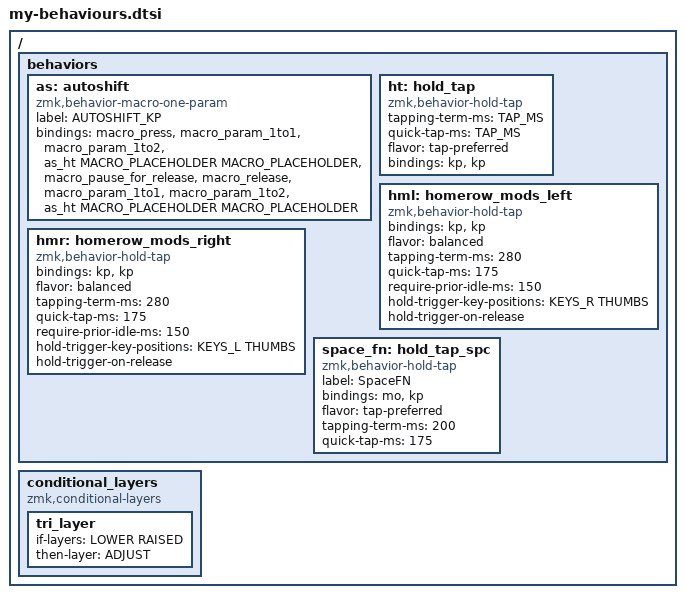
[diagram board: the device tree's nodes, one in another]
/ {
    behaviors {
    
        as: autoshift {
            compatible = "zmk,behavior-macro-one-param";
            #binding-cells = <1>;
            label = "AUTOSHIFT_KP";
            bindings =
              <&macro_press>,
              <&macro_param_1to1>,
              <&macro_param_1to2>,
              <&as_ht MACRO_PLACEHOLDER MACRO_PLACEHOLDER>,
              <&macro_pause_for_release>,
              <&macro_release>,
              <&macro_param_1to1>,
              <&macro_param_1to2>,
              <&as_ht MACRO_PLACEHOLDER MACRO_PLACEHOLDER>;
          };
        ht: hold_tap {
                compatible = "zmk,behavior-hold-tap";
                #binding-cells = <2>;
                tapping-term-ms = <TAP_MS>;
                quick-tap-ms = <TAP_MS>;
                flavor = "tap-preferred";
                bindings = <&kp>, <&kp>;
            };
         hml: homerow_mods_left {
            compatible = "zmk,behavior-hold-tap";
            #binding-cells = <2>;
            bindings = <&kp>, <&kp>;           // First param = mod, second = tap
            flavor = "balanced";                // Immediate hold on interruption
            tapping-term-ms = <280>;           // How long to wait for hold
            quick-tap-ms = <175>;              // Repeat tap timing
            require-prior-idle-ms = <150>;     // Prevent accidental holds while typing
            hold-trigger-key-positions = <KEYS_R THUMBS>;  // Only hold with opposite hand
            hold-trigger-on-release;           // Allow modifier chording
        };

        hmr: homerow_mods_right {
            compatible = "zmk,behavior-hold-tap";
            #binding-cells = <2>;
            bindings = <&kp>, <&kp>;
            flavor = "balanced";
            tapping-term-ms = <280>;
            quick-tap-ms = <175>;
            require-prior-idle-ms = <150>;
            hold-trigger-key-positions = <KEYS_L THUMBS>;
            hold-trigger-on-release;
        };
        space_fn: hold_tap_spc {
              compatible = "zmk,behavior-hold-tap";
              label = "SpaceFN";
              #binding-cells = <2>;
              bindings = <&mo>, <&kp>;
              flavor = "tap-preferred";
              tapping-term-ms = <200>;
              quick-tap-ms = <175>;
            };
    };

    conditional_layers {
        compatible = "zmk,conditional-layers";
        tri_layer {
            if-layers = <LOWER RAISED>;
            then-layer = <ADJUST>;
        };
    };
};
